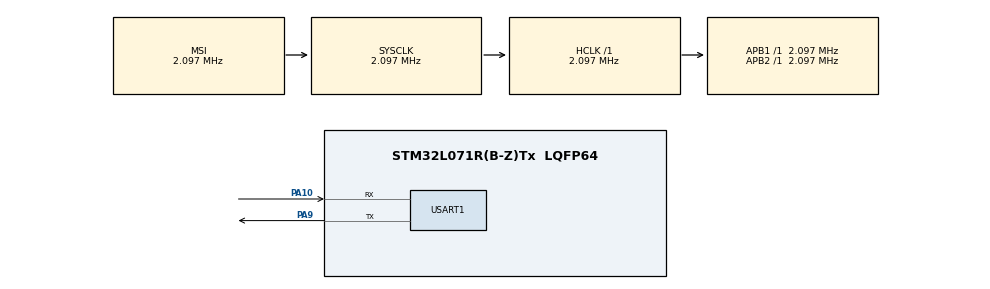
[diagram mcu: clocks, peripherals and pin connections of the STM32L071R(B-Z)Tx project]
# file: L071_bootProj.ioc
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Mcu.Family=STM32L0
Mcu.Name=STM32L071R(B-Z)Tx
Mcu.Package=LQFP64
PA10.Mode=Asynchronous
PA10.Signal=USART1_RX
PA13.Mode=Serial_Wire
PA13.Signal=SYS_SWDIO
PA14.Mode=Serial_Wire
PA14.Signal=SYS_SWCLK
PA9.Mode=Asynchronous
PA9.Signal=USART1_TX
ProjectManager.HeapSize=0x200
ProjectManager.StackSize=0x400
ProjectManager.TargetToolchain=MDK-ARM V5.32
RCC.AHBFreq_Value=2097000
RCC.APB1Freq_Value=2097000
RCC.APB1TimFreq_Value=2097000
RCC.APB2Freq_Value=2097000
RCC.APB2TimFreq_Value=2097000
RCC.HSE_VALUE=8000000
RCC.HSI16_VALUE=16000000
RCC.HSI_VALUE=16000000
RCC.LSE_VALUE=32768
RCC.MSI_VALUE=2097000
RCC.SYSCLKFreq_VALUE=2097000
RCC.VCOOutputFreq_Value=48000000
USART1.VirtualMode-Asynchronous=VM_ASYNC
board=custom

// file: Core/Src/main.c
/* USER CODE BEGIN Header */
/**
 ******************************************************************************
 * @file           : main.c
 * @brief          : Main program body
 ******************************************************************************
 * @attention
 *
 * Copyright (c) 2023 STMicroelectronics.
 * All rights reserved.
 *
 * This software is licensed under terms that can be found in the LICENSE file
 * in the root directory of this software component.
 * If no LICENSE file comes with this software, it is provided AS-IS.
 *
 ******************************************************************************
 */
/* USER CODE END Header */
#include "main.h"
#include "usart.h"
#include "gpio.h"

void SystemClock_Config(void);

/* USER CODE BEGIN 0 */
/* 开关全局中断的宏 */
#define ENABLE_INT() __set_PRIMASK(0)  /* 使能全局中断 */
#define DISABLE_INT() __set_PRIMASK(1) /* 禁止全局中断 */
#define APP_ADDR 0x08003000            /* APP地址 */

/**
 * @brief 跳转到APP
 *
 */
void JumpToApp(void)
{
    void (*SysMemBootJump)(void);     /* 声明一个函数指针 */
    __IO uint32_t AppAddr = APP_ADDR; /* APP地址 */

    /* 如果初始化了外设，需要反向初始化外设 */

    /* 设置所有时钟到默认状态，使用HSI时钟 */
    HAL_RCC_DeInit();

    /* 关闭滴答定时器，复位到默认值 */
    SysTick->CTRL = 0;
    SysTick->LOAD = 0;
    SysTick->VAL = 0;

    /* 关闭全局中断 */
    DISABLE_INT();

    /* 关闭所有中断，清除所有中断挂起标志 */
    for (uint32_t i = 0; i < 8; i++)
    {
        NVIC->ICER[i] = 0xFFFFFFFF;
        NVIC->ICPR[i] = 0xFFFFFFFF;
    }

    /* 使能全局中断 */
    ENABLE_INT();

    /* 设置SysMemBootJump为中断服务函数入口地址，首地址是MSP，地址+4是复位中断服务程序地址 */
    SysMemBootJump = (void (*)(void))(*((uint32_t *)(AppAddr + 4))); // 跳转到app程序的向量中断地址，即reset_hander开始执行app程序

    /* 设置主堆栈指针 */
    __set_MSP(*(uint32_t *)AppAddr); // 栈顶地址

    /* 在RTOS工程，这条语句很重要，设置为特权级模式，SP使用MSP指针 */
    __set_CONTROL(0);

    /* 进行跳转 也就是将SysMemBootJump 赋值给PC */
    SysMemBootJump();

    /* 跳转成功的话，不会执行到这里，用户可以在这里添加代码 */
    while (1)
    {
    }
}

/* USER CODE END 0 */

int main(void)
{
    /* USER CODE BEGIN 1 */
    __IO uint8_t *str;
    /* USER CODE END 1 */

    /* MCU Configuration--------------------------------------------------------*/

    /* Reset of all peripherals, Initializes the Flash interface and the Systick. */
    HAL_Init();

    /* Configure the system clock */
    SystemClock_Config();

    /* Initialize all configured peripherals */
    MX_GPIO_Init();
    MX_USART1_UART_Init();
    /* USER CODE BEGIN 2 */
    str = (__IO uint8_t *)(0x08080C00UL);
    printf("Bootloader running!UpgradeState:%s\r\n", str); // 固件升级存在标志位
    if (*str == 'u')
    {
        printf("uu\r\n");
    }
    JumpToApp();
    /* USER CODE END 2 */

    /* Infinite loop */
    /* USER CODE BEGIN WHILE */
    while (1)
    {

        printf("JumpFail\r\n");
        HAL_Delay(1000);
        /* USER CODE END WHILE */

    }
}

void SystemClock_Config(void)
{
    RCC_OscInitTypeDef RCC_OscInitStruct = {0};
    RCC_ClkInitTypeDef RCC_ClkInitStruct = {0};
    RCC_PeriphCLKInitTypeDef PeriphClkInit = {0};

    /** Configure the main internal regulator output voltage
     */
    __HAL_PWR_VOLTAGESCALING_CONFIG(PWR_REGULATOR_VOLTAGE_SCALE1);

    /** Initializes the RCC Oscillators according to the specified parameters
     * in the RCC_OscInitTypeDef structure.
     */
    RCC_OscInitStruct.OscillatorType = RCC_OSCILLATORTYPE_MSI;
    RCC_OscInitStruct.MSIState = RCC_MSI_ON;
    RCC_OscInitStruct.MSICalibrationValue = 0;
    RCC_OscInitStruct.MSIClockRange = RCC_MSIRANGE_5;
    RCC_OscInitStruct.PLL.PLLState = RCC_PLL_NONE;
    if (HAL_RCC_OscConfig(&RCC_OscInitStruct) != HAL_OK)
    {
        Error_Handler();
    }

    /** Initializes the CPU, AHB and APB buses clocks
     */
    RCC_ClkInitStruct.ClockType = RCC_CLOCKTYPE_HCLK | RCC_CLOCKTYPE_SYSCLK | RCC_CLOCKTYPE_PCLK1 | RCC_CLOCKTYPE_PCLK2;
    RCC_ClkInitStruct.SYSCLKSource = RCC_SYSCLKSOURCE_MSI;
    RCC_ClkInitStruct.AHBCLKDivider = RCC_SYSCLK_DIV1;
    RCC_ClkInitStruct.APB1CLKDivider = RCC_HCLK_DIV1;
    RCC_ClkInitStruct.APB2CLKDivider = RCC_HCLK_DIV1;

    if (HAL_RCC_ClockConfig(&RCC_ClkInitStruct, FLASH_LATENCY_0) != HAL_OK)
    {
        Error_Handler();
    }
    PeriphClkInit.PeriphClockSelection = RCC_PERIPHCLK_USART1;
    PeriphClkInit.Usart1ClockSelection = RCC_USART1CLKSOURCE_PCLK2;
    if (HAL_RCCEx_PeriphCLKConfig(&PeriphClkInit) != HAL_OK)
    {
        Error_Handler();
    }
}

void Error_Handler(void)
{
    __disable_irq();
    while (1)
    {
    }
}
